# ddr32ss_EMIF_CTLCFG_0F308000h register map
Vendor: Texas Instruments
Registers are 32-bit, read-write, reset 0x0 unless marked. A register's access mark holds for its fields unless they carry their own. Offsets are as the file gives them; [hi:lo] are bit positions; {n}, {i} and the like mark numbered series.

## emif_ctlcfg (part 3 of 13)
{0x0+4i} emif_ctlcfg_DENALI_CTL_{i} (i=127..130)
  [31:0] TDFI_PHYMSTR_MAX_TYPE{i-127}_F1 — Defines the DFI 4.0v2 tPHYMSTR_MAX_TYPE{i-127} timing parameter [in DFI clocks], the maximum cycles that dfi_phymstr_req can be asserted following the assertion of dfi_phymstr_ack for dfi_phymstr_type={i-127}. If programmed to a non-zero, a timing violation will cause an interrupt and bit [0] set in the PHYMSTR_ERROR_STATUS parameter. FC=1 Reset Source: ctl_amod_g_rst_n
0x20C emif_ctlcfg_DENALI_CTL_131
  [15:0] PHYMSTR_DFI4_PROMOTE_THRESHOLD_F1 — Defines the DFI[4.0 and 4.0v2] PHY master request promotion number of regular [not long] counts until the high priority request is asserted. FC=1 Reset Source: ctl_amod_g_rst_n
0x210 emif_ctlcfg_DENALI_CTL_132
  [19:0] TDFI_PHYMSTR_RESP_F1 — Defines the DFI tPHYMSTR_RESP timing parameter [in DFI clocks], the maximum cycles between a dfi_phymstr_req assertion and a dfi_phymstr_ack assertion. If programmed to a non-zero, a timing violation will cause an interrupt and bit [1] to be set to 1 in the PHYMSTR_ERROR_STATUS parameter. FC=1 Reset Source: ctl_amod_g_rst_n
0x214 emif_ctlcfg_DENALI_CTL_133
  [31:0] TDFI_PHYMSTR_MAX_F2 — Defines the DFI tPHYMSTR_MAX timing parameter [in DFI clocks], the maximum cycles that dfi_phymstr_req can be asserted following the assertion of dfi_phymstr_ack. If programmed to a non-zero, a timing violation will cause an interrupt and bit [0] set in the PHYMSTR_ERROR_STATUS parameter. FC=2 Reset Source: ctl_amod_g_rst_n
{0x0+4i} emif_ctlcfg_DENALI_CTL_{i} (i=134..137)
  [31:0] TDFI_PHYMSTR_MAX_TYPE{i-134}_F2 — Defines the DFI 4.0v2 tPHYMSTR_MAX_TYPE{i-134} timing parameter [in DFI clocks], the maximum cycles that dfi_phymstr_req can be asserted following the assertion of dfi_phymstr_ack for dfi_phymstr_type={i-134}. If programmed to a non-zero, a timing violation will cause an interrupt and bit [0] set in the PHYMSTR_ERROR_STATUS parameter. FC=2 Reset Source: ctl_amod_g_rst_n
0x228 emif_ctlcfg_DENALI_CTL_138
  [15:0] PHYMSTR_DFI4_PROMOTE_THRESHOLD_F2 — Defines the DFI[4.0 and 4.0v2] PHY master request promotion number of regular [not long] counts until the high priority request is asserted. FC=2 Reset Source: ctl_amod_g_rst_n
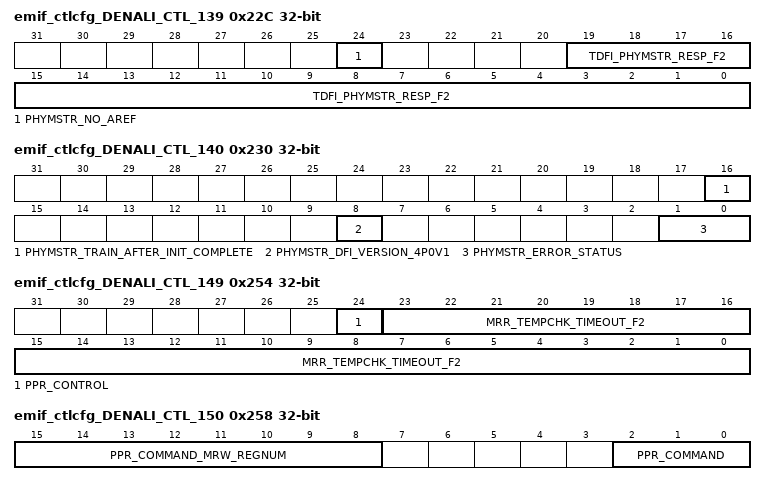
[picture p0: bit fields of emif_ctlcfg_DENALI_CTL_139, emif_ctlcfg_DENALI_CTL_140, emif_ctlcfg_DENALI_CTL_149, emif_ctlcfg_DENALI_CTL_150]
0x22C emif_ctlcfg_DENALI_CTL_139
  [24] PHYMSTR_NO_AREF — isables refreshes during the PHY master interface sequence. Set to 1 to disable. Refreshes during reset are only supported for DFI 4.0 and this parameter may be set or cleared for DFI 4.0. For all other DFI versions, this parameter must be set to 1. Reset Source: ctl_amod_g_rst_n
  [19:0] TDFI_PHYMSTR_RESP_F2 — Defines the DFI tPHYMSTR_RESP timing parameter [in DFI clocks], the maximum cycles between a dfi_phymstr_req assertion and a dfi_phymstr_ack assertion. If programmed to a non-zero, a timing violation will cause an interrupt and bit [1] to be set to 1 in the PHYMSTR_ERROR_STATUS parameter. FC=2 Reset Source: ctl_amod_g_rst_n
0x230 emif_ctlcfg_DENALI_CTL_140 access per field
  [16] PHYMSTR_TRAIN_AFTER_INIT_COMPLETE rw — Defines how the PHY will use the PHY Master Interface for training. Clear to 0 to perform training without the PHY Master Interface, or set to 1 to use the PHY Master Interface to gain control over the DFI bus after the dfi_init_complete signal assertion for the initial training. Default is cleared to 0. Reset Source: ctl_amod_g_rst_n
  [8] PHYMSTR_DFI_VERSION_4P0V1 rw — Defines the version of the DFI 4.0 specification supported. Clear to 0 for DFI 4.0 version 2 PHY Master Interface, or set to 1 for DFI 4.0 version 1 PHY Master Interface. Default is cleared to 0 for version 2. Reset Source: ctl_amod_g_rst_n
  [1:0] PHYMSTR_ERROR_STATUS ro — Identifies the source of any DFI PHY Master Interface errors. Value of 1 indicates a timing violation of the associated timing parameter. Bit [0] set indicates a TDFI_PHYMSTR_MAX or TDFI_PHYMSTR_TYPEn_MAX parmaeter violation and bit [1] set indicates a TDFI_PHYMSTR_RESP parameter violation. READ-ONLY Reset Source: ctl_amod_g_rst_n
0x234 emif_ctlcfg_DENALI_CTL_141
  [23:0] MRR_TEMPCHK_NORM_THRESHOLD_F0 — MRR temp check number of long counts until the normal priority request is asserted. FC=0 Reset Source: ctl_amod_g_rst_n
0x238 emif_ctlcfg_DENALI_CTL_142
  [23:0] MRR_TEMPCHK_HIGH_THRESHOLD_F0 — MRR temp check number of long counts until the high priority request is asserted. FC=0 Reset Source: ctl_amod_g_rst_n
0x23C emif_ctlcfg_DENALI_CTL_143
  [23:0] MRR_TEMPCHK_TIMEOUT_F0 — MRR temp check number of long counts until the timeout is asserted. FC=0 Reset Source: ctl_amod_g_rst_n
0x240 emif_ctlcfg_DENALI_CTL_144
  [23:0] MRR_TEMPCHK_NORM_THRESHOLD_F1 — MRR temp check number of long counts until the normal priority request is asserted. FC=1 Reset Source: ctl_amod_g_rst_n
0x244 emif_ctlcfg_DENALI_CTL_145
  [23:0] MRR_TEMPCHK_HIGH_THRESHOLD_F1 — MRR temp check number of long counts until the high priority request is asserted. FC=1 Reset Source: ctl_amod_g_rst_n
0x248 emif_ctlcfg_DENALI_CTL_146
  [23:0] MRR_TEMPCHK_TIMEOUT_F1 — MRR temp check number of long counts until the timeout is asserted. FC=1 Reset Source: ctl_amod_g_rst_n
0x24C emif_ctlcfg_DENALI_CTL_147
  [23:0] MRR_TEMPCHK_NORM_THRESHOLD_F2 — MRR temp check number of long counts until the normal priority request is asserted. FC=2 Reset Source: ctl_amod_g_rst_n
0x250 emif_ctlcfg_DENALI_CTL_148
  [23:0] MRR_TEMPCHK_HIGH_THRESHOLD_F2 — MRR temp check number of long counts until the high priority request is asserted. FC=2 Reset Source: ctl_amod_g_rst_n
0x254 emif_ctlcfg_DENALI_CTL_149
  [24] PPR_CONTROL — Enables the post-package repair feature. Set to 1 to enable. This parameter may only be programmed before initialization begins. Reset Source: ctl_amod_g_rst_n
  [23:0] MRR_TEMPCHK_TIMEOUT_F2 — MRR temp check number of long counts until the timeout is asserted. FC=2 Reset Source: ctl_amod_g_rst_n
0x258 emif_ctlcfg_DENALI_CTL_150 access per field
  [15:8] PPR_COMMAND_MRW_REGNUM rw — Specifies the mode register to be used. Clear to 0 for MRW0 or program to 4 for MRW4. All other values are reserved.. Reset Source: ctl_amod_g_rst_n
  [2:0] PPR_COMMAND wo — Specifies the type of PPR command. Program to 1 for pre-charge all, program to 2 for MRW, program to 3 for activate, or program to 5 for write. All other values are reserved. WRITE-ONLY Reset Source: ctl_amod_g_rst_n
0x25C emif_ctlcfg_DENALI_CTL_151
  [16:0] PPR_COMMAND_MRW_DATA — Specifies the data for the mode register write. Reset Source: ctl_amod_g_rst_n
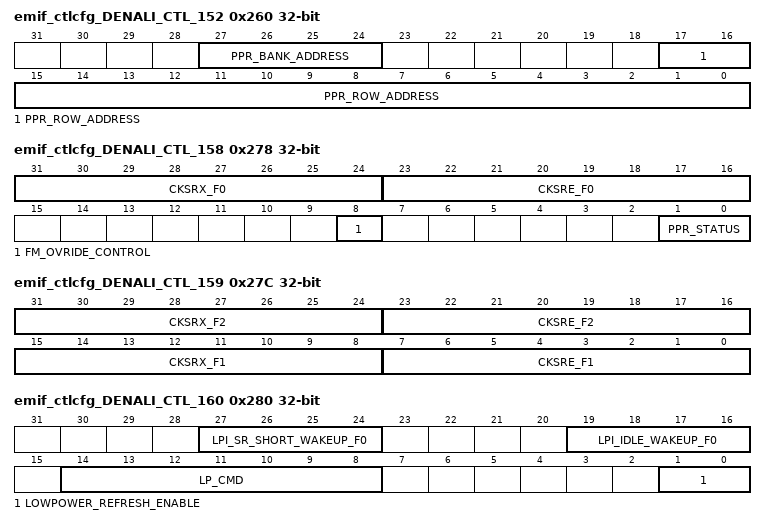
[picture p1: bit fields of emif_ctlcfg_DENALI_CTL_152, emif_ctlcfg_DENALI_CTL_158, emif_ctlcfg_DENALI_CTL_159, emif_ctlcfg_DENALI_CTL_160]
0x260 emif_ctlcfg_DENALI_CTL_152
  [27:24] PPR_BANK_ADDRESS — Specifies the bank for the row to be repaired. Reset Source: ctl_amod_g_rst_n
  [17:0] PPR_ROW_ADDRESS — Specifies the encoded row address to be repaired. Reset Source: ctl_amod_g_rst_n
0x264 emif_ctlcfg_DENALI_CTL_153
  [0] PPR_CS_ADDRESS — Specifies the chip select for the row to be repaired. Reset Source: ctl_amod_g_rst_n
{0x0+4i} emif_ctlcfg_DENALI_CTL_{i} (i=154..157)
  [31:0] PPR_DATA_{i-154} — Holds the data pattern to be written to memory for all data phases. This is specific to DDR4 memories. Reset Source: ctl_amod_g_rst_n
0x278 emif_ctlcfg_DENALI_CTL_158 access per field
  [31:24] CKSRX_F0 rw — Clock stable delay on self-refresh exit. FC=0 Reset Source: ctl_amod_g_rst_n
  [23:16] CKSRE_F0 rw — Clock hold delay on self-refresh entry. FC=0 Reset Source: ctl_amod_g_rst_n
  [8] FM_OVRIDE_CONTROL rw — Enables the FM Override feature. Set to 1 to enable. Reset Source: ctl_amod_g_rst_n
  [1:0] PPR_STATUS ro — Reports the status of the PPR operation. Bit [0] set indicates that PPR operations are now allowed and bit [1] set indicates if the last PPR command is complete. READ-ONLY Reset Source: ctl_amod_g_rst_n
0x27C emif_ctlcfg_DENALI_CTL_159
  [31:24] CKSRX_F2 — Clock stable delay on self-refresh exit. FC=2 Reset Source: ctl_amod_g_rst_n
  [23:16] CKSRE_F2 — Clock hold delay on self-refresh entry. FC=2 Reset Source: ctl_amod_g_rst_n
  [15:8] CKSRX_F1 — Clock stable delay on self-refresh exit. FC=1 Reset Source: ctl_amod_g_rst_n
  [7:0] CKSRE_F1 — Clock hold delay on self-refresh entry. FC=1 Reset Source: ctl_amod_g_rst_n
0x280 emif_ctlcfg_DENALI_CTL_160 access per field
  [27:24] LPI_SR_SHORT_WAKEUP_F0 rw — Defines the DFI tLP_WAKEUP timing parameter [in DFI clocks] to be driven when LPDDR4 memory is in the self-refresh short state [with or without memory clock gating]. For LPDDR4, SR_SHORT is used to send few commands so this wakeup time must be cleared to ZERO and no LPI request needs to be asserted. FC=0 Reset Source: ctl_amod_g_rst_n
  [19:16] LPI_IDLE_WAKEUP_F0 rw — Defines the DFI tLP_CTRL_WAKEUP timing parameter [in DFI clocks] to be driven when controller is idle. FC=0 Reset Source: ctl_amod_g_rst_n
  [14:8] LP_CMD wo — Low power software command request interface. Bit [0] controls exit, bit [1] controls entry, bits [4:2] define the low power state, bit [5] controls memory clock gating, bit [6] controls controller clock gating, and bit [7] controls lock. WRITE-ONLY Reset Source: ctl_amod_g_rst_n
  [1:0] LOWPOWER_REFRESH_ENABLE rw — Enable refreshes while in low power mode. Bit [0] controls cs0, bit [1] controls cs1, etc. Set each bit to 1 to disable. Reset Source: ctl_amod_g_rst_n
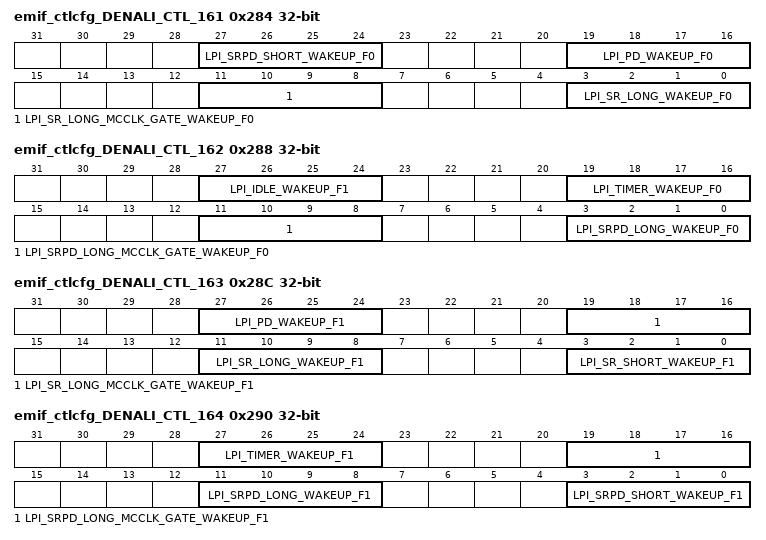
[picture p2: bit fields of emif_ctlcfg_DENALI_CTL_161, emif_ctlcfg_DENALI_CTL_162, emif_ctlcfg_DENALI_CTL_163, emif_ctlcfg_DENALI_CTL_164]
0x284 emif_ctlcfg_DENALI_CTL_161
  [27:24] LPI_SRPD_SHORT_WAKEUP_F0 — Defines the DFI tLP_WAKEUP timing parameter [in DFI clocks] to be driven when memory is in the self-refresh power-down short state [with or without memory clock gating]. FC=0 Reset Source: ctl_amod_g_rst_n
  [19:16] LPI_PD_WAKEUP_F0 — Defines the DFI tLP_WAKEUP timing parameter [in DFI clocks] to be driven when memory is in any of the power-down states [with or without memory clock gating]. FC=0 Reset Source: ctl_amod_g_rst_n
  [11:8] LPI_SR_LONG_MCCLK_GATE_WAKEUP_F0 — Defines the DFI tLP_WAKEUP timing parameter [in DFI clocks] to be driven when memory is in the self-refresh long with memory and controller clock gating state. FC=0 Reset Source: ctl_amod_g_rst_n
  [3:0] LPI_SR_LONG_WAKEUP_F0 — Defines the DFI tLP_WAKEUP timing parameter [in DFI clocks] to be driven when memory is in the self-refresh long state [with or without memory clock gating]. FC=0 Reset Source: ctl_amod_g_rst_n
0x288 emif_ctlcfg_DENALI_CTL_162
  [27:24] LPI_IDLE_WAKEUP_F1 — Defines the DFI tLP_CTRL_WAKEUP timing parameter [in DFI clocks] to be driven when controller is idle. FC=1 Reset Source: ctl_amod_g_rst_n
  [19:16] LPI_TIMER_WAKEUP_F0 — Defines the DFI tLP_WAKEUP timing parameter [in DFI clocks] to be driven when the LPI timer expires. FC=0 Reset Source: ctl_amod_g_rst_n
  [11:8] LPI_SRPD_LONG_MCCLK_GATE_WAKEUP_F0 — Defines the DFI tLP_WAKEUP timing parameter [in DFI clocks] to be driven when memory is in the self-refresh power-down long with memory and controller clock gating state. FC=0 Reset Source: ctl_amod_g_rst_n
  [3:0] LPI_SRPD_LONG_WAKEUP_F0 — Defines the DFI tLP_WAKEUP timing parameter [in DFI clocks] to be driven when memory is in the self-refresh power-down long state [with or without memory clock gating]. FC=0 Reset Source: ctl_amod_g_rst_n
0x28C emif_ctlcfg_DENALI_CTL_163
  [27:24] LPI_PD_WAKEUP_F1 — Defines the DFI tLP_WAKEUP timing parameter [in DFI clocks] to be driven when memory is in any of the power-down states [with or without memory clock gating]. FC=1 Reset Source: ctl_amod_g_rst_n
  [19:16] LPI_SR_LONG_MCCLK_GATE_WAKEUP_F1 — Defines the DFI tLP_WAKEUP timing parameter [in DFI clocks] to be driven when memory is in the self-refresh long with memory and controller clock gating state. FC=1 Reset Source: ctl_amod_g_rst_n
  [11:8] LPI_SR_LONG_WAKEUP_F1 — Defines the DFI tLP_WAKEUP timing parameter [in DFI clocks] to be driven when memory is in the self-refresh long state [with or without memory clock gating]. FC=1 Reset Source: ctl_amod_g_rst_n
  [3:0] LPI_SR_SHORT_WAKEUP_F1 — Defines the DFI tLP_WAKEUP timing parameter [in DFI clocks] to be driven when LPDDR4 memory is in the self-refresh short state [with or without memory clock gating]. For LPDDR4, SR_SHORT is used to send few commands so this wakeup time must be cleared to ZERO and no LPI request needs to be asserted. FC=1 Reset Source: ctl_amod_g_rst_n
0x290 emif_ctlcfg_DENALI_CTL_164
  [27:24] LPI_TIMER_WAKEUP_F1 — Defines the DFI tLP_WAKEUP timing parameter [in DFI clocks] to be driven when the LPI timer expires. FC=1 Reset Source: ctl_amod_g_rst_n
  [19:16] LPI_SRPD_LONG_MCCLK_GATE_WAKEUP_F1 — Defines the DFI tLP_WAKEUP timing parameter [in DFI clocks] to be driven when memory is in the self-refresh power-down long with memory and controller clock gating state. FC=1 Reset Source: ctl_amod_g_rst_n
  [11:8] LPI_SRPD_LONG_WAKEUP_F1 — Defines the DFI tLP_WAKEUP timing parameter [in DFI clocks] to be driven when memory is in the self-refresh power-down long state [with or without memory clock gating]. FC=1 Reset Source: ctl_amod_g_rst_n
  [3:0] LPI_SRPD_SHORT_WAKEUP_F1 — Defines the DFI tLP_WAKEUP timing parameter [in DFI clocks] to be driven when memory is in the self-refresh power-down short state [with or without memory clock gating]. FC=1 Reset Source: ctl_amod_g_rst_n
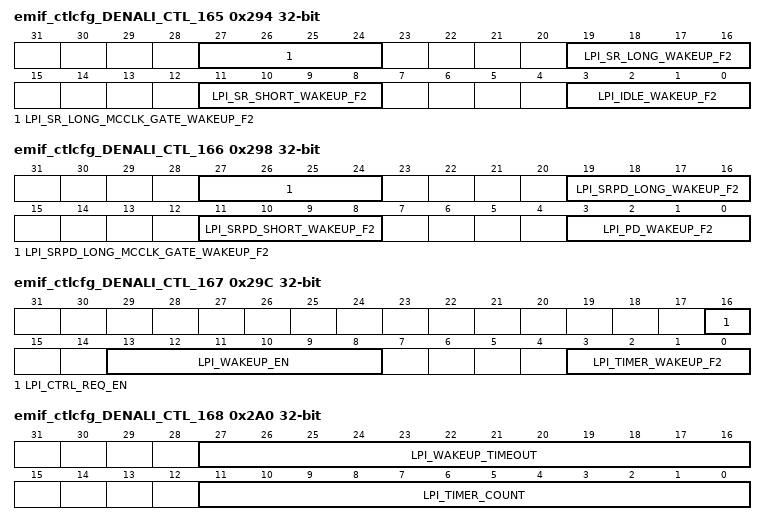
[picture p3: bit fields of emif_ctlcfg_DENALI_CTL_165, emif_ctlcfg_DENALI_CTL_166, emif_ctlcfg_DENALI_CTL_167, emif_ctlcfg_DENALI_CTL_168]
0x294 emif_ctlcfg_DENALI_CTL_165
  [27:24] LPI_SR_LONG_MCCLK_GATE_WAKEUP_F2 — Defines the DFI tLP_WAKEUP timing parameter [in DFI clocks] to be driven when memory is in the self-refresh long with memory and controller clock gating state. FC=2 Reset Source: ctl_amod_g_rst_n
  [19:16] LPI_SR_LONG_WAKEUP_F2 — Defines the DFI tLP_WAKEUP timing parameter [in DFI clocks] to be driven when memory is in the self-refresh long state [with or without memory clock gating]. FC=2 Reset Source: ctl_amod_g_rst_n
  [11:8] LPI_SR_SHORT_WAKEUP_F2 — Defines the DFI tLP_WAKEUP timing parameter [in DFI clocks] to be driven when LPDDR4 memory is in the self-refresh short state [with or without memory clock gating]. For LPDDR4, SR_SHORT is used to send few commands so this wakeup time must be cleared to ZERO and no LPI request needs to be asserted. FC=2 Reset Source: ctl_amod_g_rst_n
  [3:0] LPI_IDLE_WAKEUP_F2 — Defines the DFI tLP_CTRL_WAKEUP timing parameter [in DFI clocks] to be driven when controller is idle. FC=2 Reset Source: ctl_amod_g_rst_n
0x298 emif_ctlcfg_DENALI_CTL_166
  [27:24] LPI_SRPD_LONG_MCCLK_GATE_WAKEUP_F2 — Defines the DFI tLP_WAKEUP timing parameter [in DFI clocks] to be driven when memory is in the self-refresh power-down long with memory and controller clock gating state. FC=2 Reset Source: ctl_amod_g_rst_n
  [19:16] LPI_SRPD_LONG_WAKEUP_F2 — Defines the DFI tLP_WAKEUP timing parameter [in DFI clocks] to be driven when memory is in the self-refresh power-down long state [with or without memory clock gating]. FC=2 Reset Source: ctl_amod_g_rst_n
  [11:8] LPI_SRPD_SHORT_WAKEUP_F2 — Defines the DFI tLP_WAKEUP timing parameter [in DFI clocks] to be driven when memory is in the self-refresh power-down short state [with or without memory clock gating]. FC=2 Reset Source: ctl_amod_g_rst_n
  [3:0] LPI_PD_WAKEUP_F2 — Defines the DFI tLP_WAKEUP timing parameter [in DFI clocks] to be driven when memory is in any of the power-down states [with or without memory clock gating]. FC=2 Reset Source: ctl_amod_g_rst_n
0x29C emif_ctlcfg_DENALI_CTL_167
  [16] LPI_CTRL_REQ_EN — Enables the dfi_lpi_ctrl_req signal for the LPI. This signal is only relevant for DFI versions 3.1 and beyond. Set to 1 to enable or clear to 0 to disable. Reset Source: ctl_amod_g_rst_n
  [13:8] LPI_WAKEUP_EN — Enables the various low power state wakeup parameters for LPI request uses. Bit [0] enables controller idle wakeup, bit [1] enables power-down wakeup, bit [2] enables either self-refresh short, self-refresh long with or without mem clk gating, either self-refresh power-down short, or self-refresh power-down long with or without mem clk gating, bit [3] enables self-refresh long with mem and ctlr clk gating or self-refresh power-down long with mem and ctlr clk gating, bit [4] enables the LPI timer expire wakeup, and bit [5] is reserved. Set each bit to 1 to enable the respective LP_WAKEUP value for the LPI request. Reset Source: ctl_amod_g_rst_n
  [3:0] LPI_TIMER_WAKEUP_F2 — Defines the DFI tLP_WAKEUP timing parameter [in DFI clocks] to be driven when the LPI timer expires. FC=2 Reset Source: ctl_amod_g_rst_n
0x2A0 emif_ctlcfg_DENALI_CTL_168
  [27:16] LPI_WAKEUP_TIMEOUT — Defines the LPI timeout time, the maximum cycles between a dfi_lp_req de-assertion and a dfi_lp_ack de-assertion. If this value is exceeded, an interrupt will occur. Reset Source: ctl_amod_g_rst_n
  [11:0] LPI_TIMER_COUNT — Defines the LPI timer count. Reset Source: ctl_amod_g_rst_n
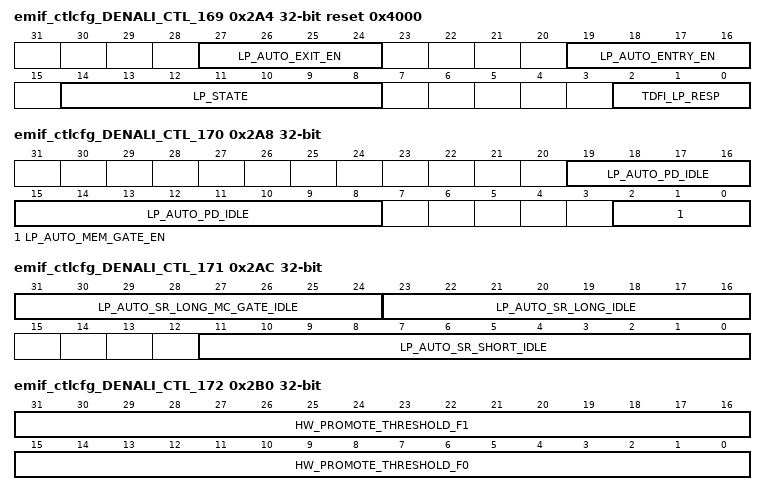
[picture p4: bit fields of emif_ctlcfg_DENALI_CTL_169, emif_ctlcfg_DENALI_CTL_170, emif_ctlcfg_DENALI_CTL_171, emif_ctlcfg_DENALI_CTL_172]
0x2A4 emif_ctlcfg_DENALI_CTL_169 access per field reset 0x4000
  [27:24] LP_AUTO_EXIT_EN rw — Enable auto exit from each of the low power states when a read or write command enters the command queue. Bit [0] controls power-down, bit [1] controls self-refresh long or self-refresh power-down long, bit [2] controls self-refresh long with memory and controller clock gating or self-refresh power-down long with memory and controller clock gating, and bit [3] controls self-refresh short or self-refresh power-down short. Set each bit to 1 to enable. Reset Source: ctl_amod_g_rst_n
  [19:16] LP_AUTO_ENTRY_EN rw — Enable auto entry into each of the low power states when the associated idle timer expires. Bit [0] controls power-down, bit [1] controls self-refresh long or self-refresh power-down long, bit [2] controls self-refresh long with memory and controller clock gating or self-refresh power-down long with memory and controller clock gating, and bit [3] controls self-refresh short or self-refresh power-down short. Set each bit to 1 to enable. Reset Source: ctl_amod_g_rst_n
  [14:8] LP_STATE ro — Low power state status parameter. Bits [5:0] indicate the current low power state and bit [6] set indicates that status bits are valid. READ-ONLY Reset Source: ctl_amod_g_rst_n
  [2:0] TDFI_LP_RESP rw — Defines the DFI tLP_RESP timing parameter [in DFI clocks], the maximum cycles between a dfi_lp_req assertion and a dfi_lp_ack assertion. Reset Source: ctl_amod_g_rst_n
0x2A8 emif_ctlcfg_DENALI_CTL_170
  [19:8] LP_AUTO_PD_IDLE — Defines the idle time [in controller clocks] until the controller will automatically issue an entry into one of the power-down low power states. Reset Source: ctl_amod_g_rst_n
  [2:0] LP_AUTO_MEM_GATE_EN — Enable memory clock gating when entering a low power state via the auto low power counters. Bit [0] controls power-down, bit [1] controls self-refresh long or self-refresh power-down long, and bit [2] controls self-refresh short or self-refresh power-down short. Set each bit to 1 to enable. Reset Source: ctl_amod_g_rst_n
0x2AC emif_ctlcfg_DENALI_CTL_171
  [31:24] LP_AUTO_SR_LONG_MC_GATE_IDLE — Defines the idle time [in long counts] until the controller will automatically issue an entry into the self-refresh long with memory and controller clock gating or self-refresh power-down long with memory and controller clock gating low power states. Reset Source: ctl_amod_g_rst_n
  [23:16] LP_AUTO_SR_LONG_IDLE — Defines the idle time [in long counts] until the controller will automatically issue an entry into the self-refresh long or self-refresh power-down long [with or without memory clock gating] low power states. Reset Source: ctl_amod_g_rst_n
  [11:0] LP_AUTO_SR_SHORT_IDLE — Defines the idle time [in controller clocks] until the controller will automatically issue an entry into the self-refresh short or self-refresh power-down short [with or without memory clock gating] low power states. Reset Source: ctl_amod_g_rst_n
0x2B0 emif_ctlcfg_DENALI_CTL_172
  [31:16] HW_PROMOTE_THRESHOLD_F1 — HW interface promotion number of long counts until the high priority request is asserted. FC=1 Reset Source: ctl_amod_g_rst_n
  [15:0] HW_PROMOTE_THRESHOLD_F0 — HW interface promotion number of long counts until the high priority request is asserted. FC=0 Reset Source: ctl_amod_g_rst_n
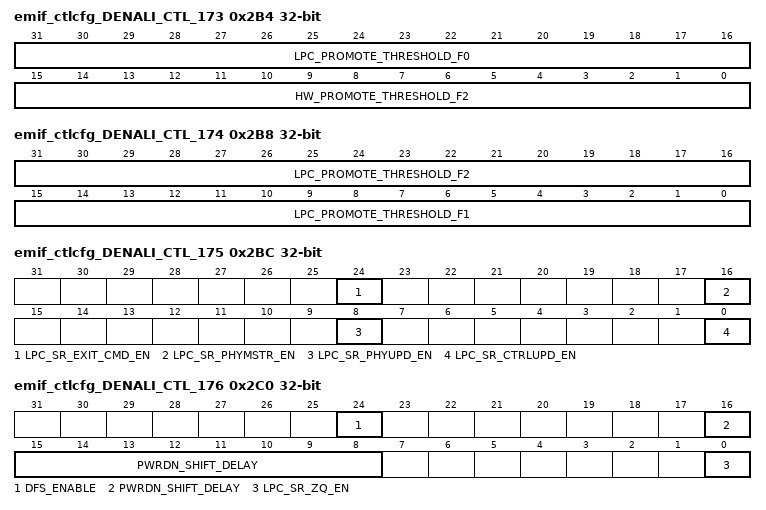
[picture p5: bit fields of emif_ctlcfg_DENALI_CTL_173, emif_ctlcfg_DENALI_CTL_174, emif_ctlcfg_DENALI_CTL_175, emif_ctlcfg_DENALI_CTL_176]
0x2B4 emif_ctlcfg_DENALI_CTL_173
  [31:16] LPC_PROMOTE_THRESHOLD_F0 — LPC promotion number of long counts until the high priority request is asserted for frequency copy 4. Applies to SW and auto low power commands. FC=0 Reset Source: ctl_amod_g_rst_n
  [15:0] HW_PROMOTE_THRESHOLD_F2 — HW interface promotion number of long counts until the high priority request is asserted. FC=2 Reset Source: ctl_amod_g_rst_n
0x2B8 emif_ctlcfg_DENALI_CTL_174
  [31:16] LPC_PROMOTE_THRESHOLD_F2 — LPC promotion number of long counts until the high priority request is asserted for frequency copy 4. Applies to SW and auto low power commands. FC=2 Reset Source: ctl_amod_g_rst_n
  [15:0] LPC_PROMOTE_THRESHOLD_F1 — LPC promotion number of long counts until the high priority request is asserted for frequency copy 4. Applies to SW and auto low power commands. FC=1 Reset Source: ctl_amod_g_rst_n
0x2BC emif_ctlcfg_DENALI_CTL_175
  [24] LPC_SR_EXIT_CMD_EN — Enable LPC to execute any of the commands on self-refresh exit while exiting. Set to 1 to enable. Reset Source: ctl_amod_g_rst_n
  [16] LPC_SR_PHYMSTR_EN — Enable LPC to execute a DFI PHY Master request on a self-refresh exit sequence. Set to 1 to enable. Reset Source: ctl_amod_g_rst_n
  [8] LPC_SR_PHYUPD_EN — Enable LPC to execute a DFI PHY update on a self-refresh exit sequence. Set to 1 to enable. Reset Source: ctl_amod_g_rst_n
  [0] LPC_SR_CTRLUPD_EN — Enable LPC to execute a DFI control update on a self-refresh exit sequence. Set to 1 to enable. Reset Source: ctl_amod_g_rst_n
0x2C0 emif_ctlcfg_DENALI_CTL_176
  [24] DFS_ENABLE — Enable hardware dynamic frequency scaling. Set to 1 to enable. Reset Source: ctl_amod_g_rst_n
  [16:8] PWRDN_SHIFT_DELAY — This parameter should be programmed to zero. Manual adjustment of inhibit_pwrdn_shift in memcd_strategy_data_delay. Reset Source: ctl_amod_g_rst_n
  [0] LPC_SR_ZQ_EN — Enable LPC to execute a ZQ calibration on a self-refresh exit sequence. Set to 1 to enable. Reset Source: ctl_amod_g_rst_n
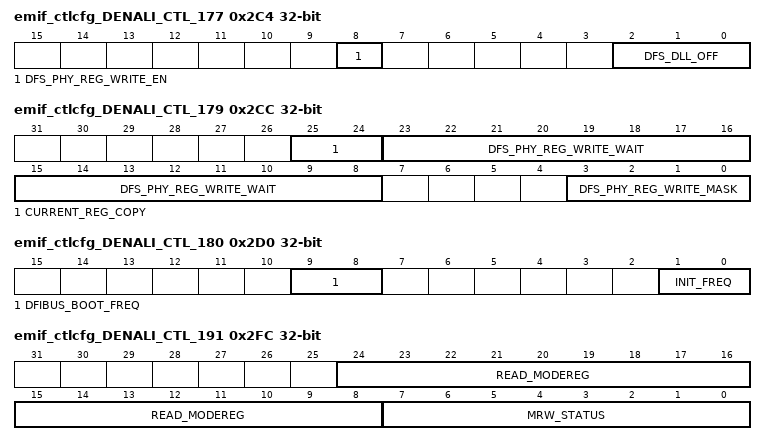
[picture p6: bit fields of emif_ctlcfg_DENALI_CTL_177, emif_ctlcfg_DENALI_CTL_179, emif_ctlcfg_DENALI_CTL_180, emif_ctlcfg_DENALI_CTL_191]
0x2C4 emif_ctlcfg_DENALI_CTL_177
  [8] DFS_PHY_REG_WRITE_EN — Enable a register write to the PHY during a frequency change. Set to 1 to enable. Reset Source: ctl_amod_g_rst_n
  [2:0] DFS_DLL_OFF — Defines if the memory DLL must be off for the associated frequency set. Bit [0] corresponds to frequency set 0, bit [1] corresponds to frequency set 1, etc. Set each bit to 1 to require DLL off. Reset Source: ctl_amod_g_rst_n
0x2C8 emif_ctlcfg_DENALI_CTL_178
  [31:0] DFS_PHY_REG_WRITE_ADDR — Register address which will be written during a frequency change. Must be a PHY register address. Reset Source: ctl_amod_g_rst_n
0x2CC emif_ctlcfg_DENALI_CTL_179 access per field
  [25:24] CURRENT_REG_COPY ro — Indicates the current copy of timing parameters that is in use by the controller. Reset Source: ctl_amod_g_rst_n
  [23:8] DFS_PHY_REG_WRITE_WAIT rw — Defines the number of DFI PHY clocks that the controller will wait after issuing the register write to the PHY during a frequency change. Reset Source: ctl_amod_g_rst_n
  [3:0] DFS_PHY_REG_WRITE_MASK rw — Register mask which will be written during a frequency change. Reset Source: ctl_amod_g_rst_n
0x2D0 emif_ctlcfg_DENALI_CTL_180
  [9:8] DFIBUS_BOOT_FREQ — Defines the DFI bus boot frequency register copy Reset Source: ctl_amod_g_rst_n
  [1:0] INIT_FREQ — Specifies what frequency register copy will be in use by the memory after initialization completes. Reset Source: ctl_amod_g_rst_n
{0x0+4i} emif_ctlcfg_DENALI_CTL_{i} (i=181..183)
  [31:0] DFS_PHY_REG_WRITE_DATA_F{i-181} — Register data which will be written during a frequency change. FC={i-181} Reset Source: ctl_amod_g_rst_n
0x2E0 emif_ctlcfg_DENALI_CTL_184
  [23:0] TDFI_INIT_START_F0 — Defines the DFI tINIT_START timing parameter [in DFI clocks], the maximum number of cycles between a dfi_init_start assertion and a dfi_init_complete de-assertion from the PHY. FC=0 Reset Source: ctl_amod_g_rst_n
0x2E4 emif_ctlcfg_DENALI_CTL_185
  [23:0] TDFI_INIT_COMPLETE_F0 — Defines the DFI tINIT_COMPLETE timing parameter [in DFI clocks], the maximum cycles between a dfi_init_start de-assertion and a dfi_init_complete assertion from the PHY. FC=0 Reset Source: ctl_amod_g_rst_n
0x2E8 emif_ctlcfg_DENALI_CTL_186
  [23:0] TDFI_INIT_START_F1 — Defines the DFI tINIT_START timing parameter [in DFI clocks], the maximum number of cycles between a dfi_init_start assertion and a dfi_init_complete de-assertion from the PHY. FC=1 Reset Source: ctl_amod_g_rst_n
0x2EC emif_ctlcfg_DENALI_CTL_187
  [23:0] TDFI_INIT_COMPLETE_F1 — Defines the DFI tINIT_COMPLETE timing parameter [in DFI clocks], the maximum cycles between a dfi_init_start de-assertion and a dfi_init_complete assertion from the PHY. FC=1 Reset Source: ctl_amod_g_rst_n
0x2F0 emif_ctlcfg_DENALI_CTL_188
  [23:0] TDFI_INIT_START_F2 — Defines the DFI tINIT_START timing parameter [in DFI clocks], the maximum number of cycles between a dfi_init_start assertion and a dfi_init_complete de-assertion from the PHY. FC=2 Reset Source: ctl_amod_g_rst_n
0x2F4 emif_ctlcfg_DENALI_CTL_189
  [23:0] TDFI_INIT_COMPLETE_F2 — Defines the DFI tINIT_COMPLETE timing parameter [in DFI clocks], the maximum cycles between a dfi_init_start de-assertion and a dfi_init_complete assertion from the PHY. FC=2 Reset Source: ctl_amod_g_rst_n
0x2F8 emif_ctlcfg_DENALI_CTL_190
  [26:0] WRITE_MODEREG — Write memory mode register data to the DRAMs. Bits [7:0] define the memory mode register number if bit [23] is set, bits [15:8] define the chip select if bit [24] is clear, bits [23:16] define which memory mode register/s to write, bit [24] defines whether all chip selects will be written, and bit [25] triggers the write. Reset Source: ctl_amod_g_rst_n
0x2FC emif_ctlcfg_DENALI_CTL_191 access per field
  [24:8] READ_MODEREG rw — Read the specified memory mode register from specified chip when start bit set. Bits [7:0] define the memory mode register and bits [15:8] define the chip select. Set bit [16] to 1 to trigger. Reset Source: ctl_amod_g_rst_n
  [7:0] MRW_STATUS ro — Write memory mode register status. Bit [0] set indicates a WRITE_MODEREG parameter programming error. Bit [1] set indicates a PASR error. Bit [2] is Reserved. Bit [3] set indicates a self-refresh or deep power-down error. Bit [4] set indicates that a write to MR3 or MR11 was attempted [WRITE_MODEREG bit [25] was asserted with bit [17] set, or bit [23] was asserted with bits [7:0] defining MR3 or MR11] during tZQCAL after a ZQ calibration start command. READ-ONLY Reset Source: ctl_amod_g_rst_n
0x300 emif_ctlcfg_DENALI_CTL_192 ro
  [31:0] PERIPHERAL_MRR_DATA_0 — Data and chip returned from memory mode register read requested by the READ_MODEREG parameter. Bits [7:0] indicate the read data and bits [15:8] indicate the chip. READ-ONLY Reset Source: ctl_amod_g_rst_n
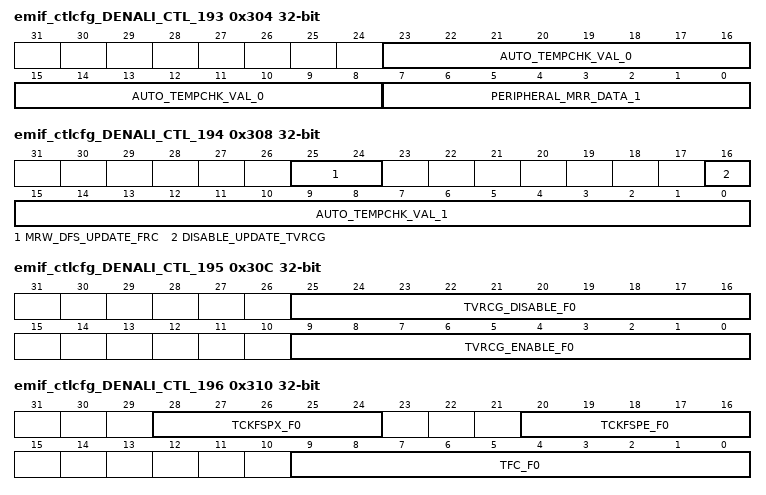
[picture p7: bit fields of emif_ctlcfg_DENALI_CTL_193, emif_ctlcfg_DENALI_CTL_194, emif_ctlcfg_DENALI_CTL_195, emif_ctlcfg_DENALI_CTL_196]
0x304 emif_ctlcfg_DENALI_CTL_193 ro
  [23:8] AUTO_TEMPCHK_VAL_0 — MR4 data for all devices accessed by automatic MRR commands. Bits [3:0] correlate to the device on the lower byte, bits [7:4] correlate to the devices on the 2nd byte etc. Value indicates the OP7, OP2, OP1 and OP0 bits. READ-ONLY. Reset Source: ctl_amod_g_rst_n
  [7:0] PERIPHERAL_MRR_DATA_1 — Data and chip returned from memory mode register read requested by the READ_MODEREG parameter. Bits [7:0] indicate the read data and bits [15:8] indicate the chip. READ-ONLY Reset Source: ctl_amod_g_rst_n
0x308 emif_ctlcfg_DENALI_CTL_194 access per field
  [25:24] MRW_DFS_UPDATE_FRC rw — Defines the frequency register set to use when doing a software MRW with WRITE_MODEREG bit [26]. Reset Source: ctl_amod_g_rst_n
  [16] DISABLE_UPDATE_TVRCG rw — Bypass changing for TVRCG during a DFS operation. Set to 1 to skip TVRCG. Reset Source: ctl_amod_g_rst_n
  [15:0] AUTO_TEMPCHK_VAL_1 ro — MR4 data for all devices accessed by automatic MRR commands. Bits [3:0] correlate to the device on the lower byte, bits [7:4] correlate to the devices on the 2nd byte etc. Value indicates the OP7, OP2, OP1 and OP0 bits. READ-ONLY. Reset Source: ctl_amod_g_rst_n
0x30C emif_ctlcfg_DENALI_CTL_195
  [25:16] TVRCG_DISABLE_F0 — JEDEC TVRCG_DISABLE time. FC=0 Reset Source: ctl_amod_g_rst_n
  [9:0] TVRCG_ENABLE_F0 — JEDEC TVRCG_ENABLE time. FC=0 Reset Source: ctl_amod_g_rst_n
0x310 emif_ctlcfg_DENALI_CTL_196
  [28:24] TCKFSPX_F0 — JEDEC TCKFSPX, the frequency set point switching time. FC=0 Reset Source: ctl_amod_g_rst_n
  [20:16] TCKFSPE_F0 — JEDEC TCKFSPE, the frequency set point switching time. FC=0 Reset Source: ctl_amod_g_rst_n
  [9:0] TFC_F0 — JEDEC TFC, the frequency set point switching time. FC=0 Reset Source: ctl_amod_g_rst_n
0x314 emif_ctlcfg_DENALI_CTL_197
  [19:0] TVREF_LONG_F0 — JEDEC TVREF, design will always use the long value. FC=0 Reset Source: ctl_amod_g_rst_n
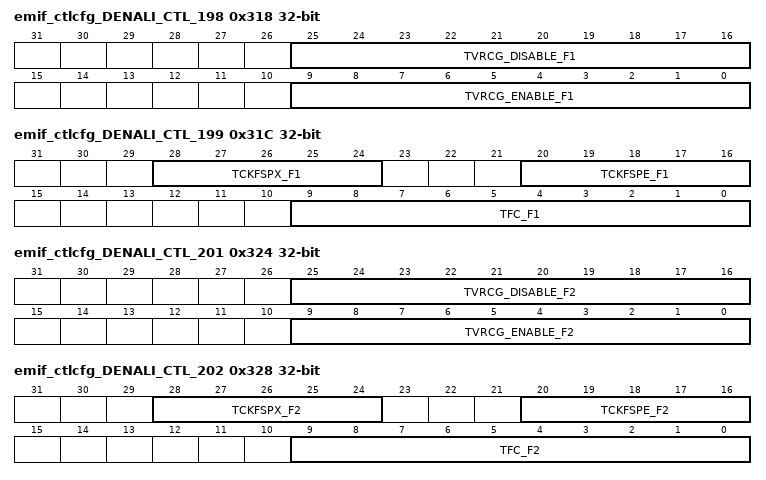
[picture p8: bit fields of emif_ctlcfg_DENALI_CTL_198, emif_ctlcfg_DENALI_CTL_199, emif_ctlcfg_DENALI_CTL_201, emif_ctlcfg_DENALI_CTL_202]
0x318 emif_ctlcfg_DENALI_CTL_198
  [25:16] TVRCG_DISABLE_F1 — JEDEC TVRCG_DISABLE time. FC=1 Reset Source: ctl_amod_g_rst_n
  [9:0] TVRCG_ENABLE_F1 — JEDEC TVRCG_ENABLE time. FC=1 Reset Source: ctl_amod_g_rst_n
0x31C emif_ctlcfg_DENALI_CTL_199
  [28:24] TCKFSPX_F1 — JEDEC TCKFSPX, the frequency set point switching time. FC=1 Reset Source: ctl_amod_g_rst_n
  [20:16] TCKFSPE_F1 — JEDEC TCKFSPE, the frequency set point switching time. FC=1 Reset Source: ctl_amod_g_rst_n
  [9:0] TFC_F1 — JEDEC TFC, the frequency set point switching time. FC=1 Reset Source: ctl_amod_g_rst_n
0x320 emif_ctlcfg_DENALI_CTL_200
  [19:0] TVREF_LONG_F1 — JEDEC TVREF, design will always use the long value. FC=1 Reset Source: ctl_amod_g_rst_n
0x324 emif_ctlcfg_DENALI_CTL_201
  [25:16] TVRCG_DISABLE_F2 — JEDEC TVRCG_DISABLE time. FC=2 Reset Source: ctl_amod_g_rst_n
  [9:0] TVRCG_ENABLE_F2 — JEDEC TVRCG_ENABLE time. FC=2 Reset Source: ctl_amod_g_rst_n
0x328 emif_ctlcfg_DENALI_CTL_202
  [28:24] TCKFSPX_F2 — JEDEC TCKFSPX, the frequency set point switching time. FC=2 Reset Source: ctl_amod_g_rst_n
  [20:16] TCKFSPE_F2 — JEDEC TCKFSPE, the frequency set point switching time. FC=2 Reset Source: ctl_amod_g_rst_n
  [9:0] TFC_F2 — JEDEC TFC, the frequency set point switching time. FC=2 Reset Source: ctl_amod_g_rst_n
0x32C emif_ctlcfg_DENALI_CTL_203
  [19:0] TVREF_LONG_F2 — JEDEC TVREF, design will always use the long value. FC=2 Reset Source: ctl_amod_g_rst_n
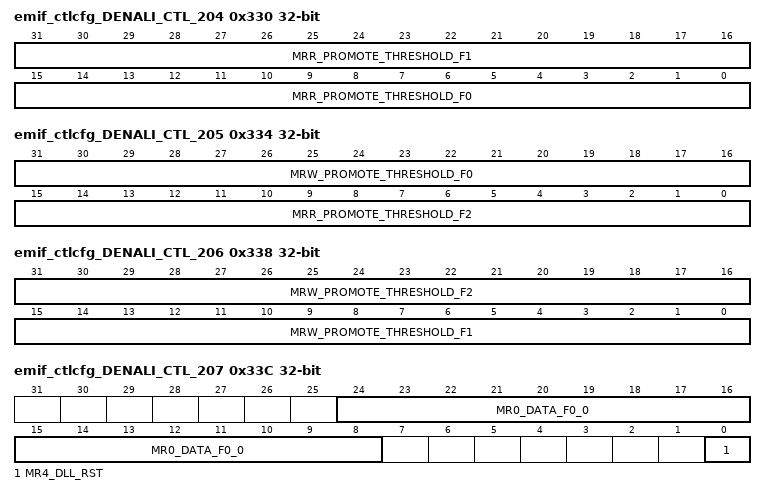
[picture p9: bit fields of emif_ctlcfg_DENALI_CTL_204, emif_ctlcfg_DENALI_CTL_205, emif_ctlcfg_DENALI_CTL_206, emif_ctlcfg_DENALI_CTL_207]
0x330 emif_ctlcfg_DENALI_CTL_204
  [31:16] MRR_PROMOTE_THRESHOLD_F1 — MRR promotion number of long counts until the high priority request is asserted. Applies to SW MRR commands. FC=1 Reset Source: ctl_amod_g_rst_n
  [15:0] MRR_PROMOTE_THRESHOLD_F0 — MRR promotion number of long counts until the high priority request is asserted. Applies to SW MRR commands. FC=0 Reset Source: ctl_amod_g_rst_n
0x334 emif_ctlcfg_DENALI_CTL_205
  [31:16] MRW_PROMOTE_THRESHOLD_F0 — MRW promotion number of long counts until the high priority request is asserted. Applies to SW MRW commands. FC=0 Reset Source: ctl_amod_g_rst_n
  [15:0] MRR_PROMOTE_THRESHOLD_F2 — MRR promotion number of long counts until the high priority request is asserted. Applies to SW MRR commands. FC=2 Reset Source: ctl_amod_g_rst_n
0x338 emif_ctlcfg_DENALI_CTL_206
  [31:16] MRW_PROMOTE_THRESHOLD_F2 — MRW promotion number of long counts until the high priority request is asserted. Applies to SW MRW commands. FC=2 Reset Source: ctl_amod_g_rst_n
  [15:0] MRW_PROMOTE_THRESHOLD_F1 — MRW promotion number of long counts until the high priority request is asserted. Applies to SW MRW commands. FC=1 Reset Source: ctl_amod_g_rst_n
0x33C emif_ctlcfg_DENALI_CTL_207
  [24:8] MR0_DATA_F0_0 — Data to program into memory mode register 0. FC=0 Reset Source: ctl_amod_g_rst_n
  [0] MR4_DLL_RST — Asserted if DRAM DLL Reset bit resides in MR4. Reset Source: ctl_amod_g_rst_n
0x340 emif_ctlcfg_DENALI_CTL_208
  [16:0] MR1_DATA_F0_0 — Data to program into memory mode register 1. FC=0 Reset Source: ctl_amod_g_rst_n
0x344 emif_ctlcfg_DENALI_CTL_209
  [16:0] MR2_DATA_F0_0 — Data to program into memory mode register 2. FC=0 Reset Source: ctl_amod_g_rst_n
{0x0+4i} emif_ctlcfg_DENALI_CTL_{i} (i=210..212)
  [16:0] MR{i-210}_DATA_F1_0 — Data to program into memory mode register {i-210}. FC=1 Reset Source: ctl_amod_g_rst_n
{0x0+4i} emif_ctlcfg_DENALI_CTL_{i} (i=213..215)
  [16:0] MR{i-213}_DATA_F2_0 — Data to program into memory mode register {i-213}. FC=2 Reset Source: ctl_amod_g_rst_n
{0x0+4i} emif_ctlcfg_DENALI_CTL_{i} (i=216..218)
  [16:0] MR{i-216}_DATA_F0_1 — Data to program into memory mode register {i-216}. FC=0 Reset Source: ctl_amod_g_rst_n
{0x0+4i} emif_ctlcfg_DENALI_CTL_{i} (i=219..221)
  [16:0] MR{i-219}_DATA_F1_1 — Data to program into memory mode register {i-219}. FC=1 Reset Source: ctl_amod_g_rst_n
{0x0+4i} emif_ctlcfg_DENALI_CTL_{i} (i=222..224)
  [16:0] MR{i-222}_DATA_F2_1 — Data to program into memory mode register {i-222}. FC=2 Reset Source: ctl_amod_g_rst_n
0x384 emif_ctlcfg_DENALI_CTL_225
  [16:0] MRSINGLE_DATA_0 — Data to program into memory mode register single write. Reset Source: ctl_amod_g_rst_n
0x388 emif_ctlcfg_DENALI_CTL_226
  [16:0] MRSINGLE_DATA_1 — Data to program into memory mode register single write. Reset Source: ctl_amod_g_rst_n
{0x0+4i} emif_ctlcfg_DENALI_CTL_{i} (i=227..229)
  [16:0] MR3_DATA_F{i-227}_0 — Data to program into memory mode register 3. FC={i-227} Reset Source: ctl_amod_g_rst_n
{0x0+4i} emif_ctlcfg_DENALI_CTL_{i} (i=230..232)
  [16:0] MR3_DATA_F{i-230}_1 — Data to program into memory mode register 3. FC={i-230} Reset Source: ctl_amod_g_rst_n
{0x0+4i} emif_ctlcfg_DENALI_CTL_{i} (i=233..235)
  [16:0] MR4_DATA_F{i-233}_0 — Data to program into memory mode register 4. FC={i-233} Reset Source: ctl_amod_g_rst_n
{0x0+4i} emif_ctlcfg_DENALI_CTL_{i} (i=236..238)
  [16:0] MR4_DATA_F{i-236}_1 — Data to program into memory mode register 4. FC={i-236} Reset Source: ctl_amod_g_rst_n
{0x0+4i} emif_ctlcfg_DENALI_CTL_{i} (i=239..241)
  [16:0] MR5_DATA_F{i-239}_0 — Data to program into memory mode register 5. FC={i-239} Reset Source: ctl_amod_g_rst_n
{0x0+4i} emif_ctlcfg_DENALI_CTL_{i} (i=242..244)
  [16:0] MR5_DATA_F{i-242}_1 — Data to program into memory mode register 5. FC={i-242} Reset Source: ctl_amod_g_rst_n
{0x0+4i} emif_ctlcfg_DENALI_CTL_{i} (i=245..247)
  [16:0] MR6_DATA_F{i-245}_0 — Data to program into memory mode register 6. FC={i-245} Reset Source: ctl_amod_g_rst_n
0x3E0 emif_ctlcfg_DENALI_CTL_248
  [16:0] MR6_DATA_F0_1 — Data to program into memory mode register 6. FC=0 Reset Source: ctl_amod_g_rst_n
0x3E4 emif_ctlcfg_DENALI_CTL_249
  [16:0] MR6_DATA_F1_1 — Data to program into memory mode register 6. FC=1 Reset Source: ctl_amod_g_rst_n
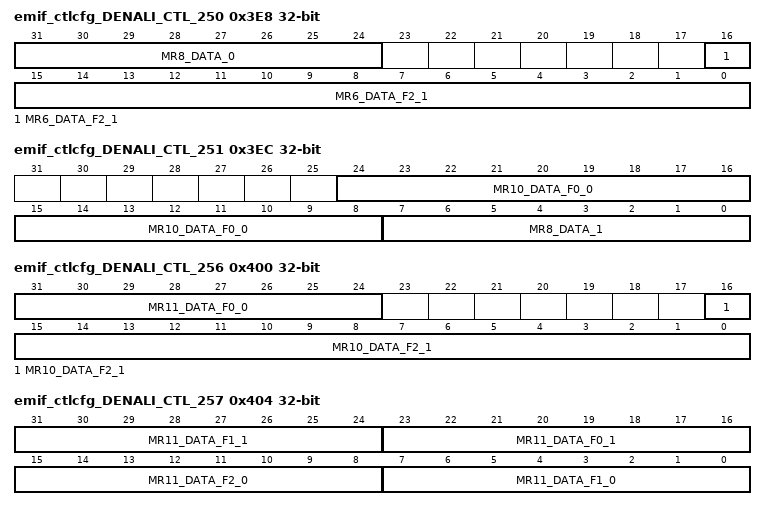
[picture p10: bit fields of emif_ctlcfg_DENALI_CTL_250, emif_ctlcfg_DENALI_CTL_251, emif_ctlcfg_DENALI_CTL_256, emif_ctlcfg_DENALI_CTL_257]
0x3E8 emif_ctlcfg_DENALI_CTL_250 access per field
  [31:24] MR8_DATA_0 ro — Data to program into memory mode register 8 for each chip select. READ-ONLY. Reset Source: ctl_amod_g_rst_n
  [16:0] MR6_DATA_F2_1 rw — Data to program into memory mode register 6. FC=2 Reset Source: ctl_amod_g_rst_n
0x3EC emif_ctlcfg_DENALI_CTL_251 access per field
  [24:8] MR10_DATA_F0_0 rw — Data to program into memory mode register 10. FC=0 Reset Source: ctl_amod_g_rst_n
  [7:0] MR8_DATA_1 ro — Data to program into memory mode register 8 for each chip select. READ-ONLY. Reset Source: ctl_amod_g_rst_n
0x3F0 emif_ctlcfg_DENALI_CTL_252
  [16:0] MR10_DATA_F1_0 — Data to program into memory mode register 10. FC=1 Reset Source: ctl_amod_g_rst_n
0x3F4 emif_ctlcfg_DENALI_CTL_253
  [16:0] MR10_DATA_F2_0 — Data to program into memory mode register 10. FC=2 Reset Source: ctl_amod_g_rst_n
0x3F8 emif_ctlcfg_DENALI_CTL_254
  [16:0] MR10_DATA_F0_1 — Data to program into memory mode register 10. FC=0 Reset Source: ctl_amod_g_rst_n
0x3FC emif_ctlcfg_DENALI_CTL_255
  [16:0] MR10_DATA_F1_1 — Data to program into memory mode register 10. FC=1 Reset Source: ctl_amod_g_rst_n
0x400 emif_ctlcfg_DENALI_CTL_256
  [31:24] MR11_DATA_F0_0 — Data to program into memory mode register 11. FC=0 Reset Source: ctl_amod_g_rst_n
  [16:0] MR10_DATA_F2_1 — Data to program into memory mode register 10. FC=2 Reset Source: ctl_amod_g_rst_n
0x404 emif_ctlcfg_DENALI_CTL_257
  [31:24] MR11_DATA_F1_1 — Data to program into memory mode register 11. FC=1 Reset Source: ctl_amod_g_rst_n
  [23:16] MR11_DATA_F0_1 — Data to program into memory mode register 11. FC=0 Reset Source: ctl_amod_g_rst_n
  [15:8] MR11_DATA_F2_0 — Data to program into memory mode register 11. FC=2 Reset Source: ctl_amod_g_rst_n
  [7:0] MR11_DATA_F1_0 — Data to program into memory mode register 11. FC=1 Reset Source: ctl_amod_g_rst_n
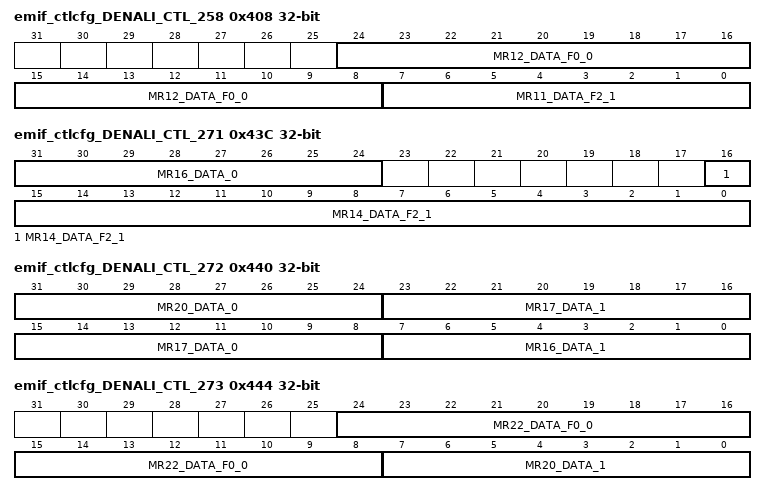
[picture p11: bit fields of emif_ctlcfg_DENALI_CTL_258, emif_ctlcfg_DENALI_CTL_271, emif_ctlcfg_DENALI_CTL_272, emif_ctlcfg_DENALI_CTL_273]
0x408 emif_ctlcfg_DENALI_CTL_258
  [24:8] MR12_DATA_F0_0 — Data to program into memory mode register 12. FC=0 Reset Source: ctl_amod_g_rst_n
  [7:0] MR11_DATA_F2_1 — Data to program into memory mode register 11. FC=2 Reset Source: ctl_amod_g_rst_n
0x40C emif_ctlcfg_DENALI_CTL_259
  [16:0] MR12_DATA_F1_0 — Data to program into memory mode register 12. FC=1 Reset Source: ctl_amod_g_rst_n
0x410 emif_ctlcfg_DENALI_CTL_260
  [16:0] MR12_DATA_F2_0 — Data to program into memory mode register 12. FC=2 Reset Source: ctl_amod_g_rst_n
{0x0+4i} emif_ctlcfg_DENALI_CTL_{i} (i=261..263)
  [16:0] MR12_DATA_F{i-261}_1 — Data to program into memory mode register 12. FC={i-261} Reset Source: ctl_amod_g_rst_n
0x420 emif_ctlcfg_DENALI_CTL_264
  [16:0] MR13_DATA_0 — Data to program into memory mode register 13. Reset Source: ctl_amod_g_rst_n
0x424 emif_ctlcfg_DENALI_CTL_265
  [16:0] MR13_DATA_1 — Data to program into memory mode register 13. Reset Source: ctl_amod_g_rst_n
{0x0+4i} emif_ctlcfg_DENALI_CTL_{i} (i=266..268)
  [16:0] MR14_DATA_F{i-266}_0 — Data to program into memory mode register 14. FC={i-266} Reset Source: ctl_amod_g_rst_n
0x434 emif_ctlcfg_DENALI_CTL_269
  [16:0] MR14_DATA_F0_1 — Data to program into memory mode register 14. FC=0 Reset Source: ctl_amod_g_rst_n
0x438 emif_ctlcfg_DENALI_CTL_270
  [16:0] MR14_DATA_F1_1 — Data to program into memory mode register 14. FC=1 Reset Source: ctl_amod_g_rst_n
0x43C emif_ctlcfg_DENALI_CTL_271
  [31:24] MR16_DATA_0 — Data to program into memory mode register 16. Reset Source: ctl_amod_g_rst_n
  [16:0] MR14_DATA_F2_1 — Data to program into memory mode register 14. FC=2 Reset Source: ctl_amod_g_rst_n
0x440 emif_ctlcfg_DENALI_CTL_272
  [31:24] MR20_DATA_0 — Data to program into memory mode register 20. Reset Source: ctl_amod_g_rst_n
  [23:16] MR17_DATA_1 — Data to program into memory mode register 17. Reset Source: ctl_amod_g_rst_n
  [15:8] MR17_DATA_0 — Data to program into memory mode register 17. Reset Source: ctl_amod_g_rst_n
  [7:0] MR16_DATA_1 — Data to program into memory mode register 16. Reset Source: ctl_amod_g_rst_n
0x444 emif_ctlcfg_DENALI_CTL_273
  [24:8] MR22_DATA_F0_0 — Data to program into memory mode register 22. FC=0 Reset Source: ctl_amod_g_rst_n
  [7:0] MR20_DATA_1 — Data to program into memory mode register 20. Reset Source: ctl_amod_g_rst_n
0x448 emif_ctlcfg_DENALI_CTL_274
  [16:0] MR22_DATA_F1_0 — Data to program into memory mode register 22. FC=1 Reset Source: ctl_amod_g_rst_n
0x44C emif_ctlcfg_DENALI_CTL_275
  [16:0] MR22_DATA_F2_0 — Data to program into memory mode register 22. FC=2 Reset Source: ctl_amod_g_rst_n
{0x0+4i} emif_ctlcfg_DENALI_CTL_{i} (i=276..278)
  [16:0] MR22_DATA_F{i-276}_1 — Data to program into memory mode register 22. FC={i-276} Reset Source: ctl_amod_g_rst_n
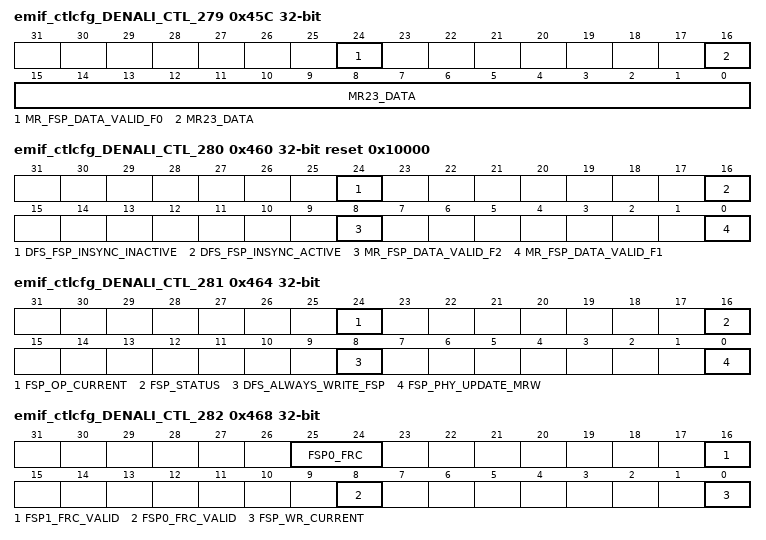
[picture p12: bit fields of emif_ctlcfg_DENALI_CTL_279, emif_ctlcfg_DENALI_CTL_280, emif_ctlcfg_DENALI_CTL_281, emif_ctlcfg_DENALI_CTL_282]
0x45C emif_ctlcfg_DENALI_CTL_279
  [24] MR_FSP_DATA_VALID_F0 — Indicates that, at this frequency, memory was trained and the associated data has been loaded into the MRx_DATA parameter[s]. Value of 1 means memory was trained. FC=0 Reset Source: ctl_amod_g_rst_n
  [16:0] MR23_DATA — Data to program into memory mode register 23. Reset Source: ctl_amod_g_rst_n
0x460 emif_ctlcfg_DENALI_CTL_280 access per field reset 0x10000
  [24] DFS_FSP_INSYNC_INACTIVE ro — When cleared, this indicates that the contents in memcd_param is new that the values in memory's MRx FSP reg and if a dfs occurs, they need to be updated. READ-ONLY Reset Source: ctl_amod_g_rst_n
  [16] DFS_FSP_INSYNC_ACTIVE ro — When cleared, this indicates that the contents in memcd_param is new that the values in memory's MRx FSP reg and if a dfs occurs, they need to be updated. READ-ONLY Reset Source: ctl_amod_g_rst_n
  [8] MR_FSP_DATA_VALID_F2 rw — Indicates that, at this frequency, memory was trained and the associated data has been loaded into the MRx_DATA parameter[s]. Value of 1 means memory was trained. FC=2 Reset Source: ctl_amod_g_rst_n
  [0] MR_FSP_DATA_VALID_F1 rw — Indicates that, at this frequency, memory was trained and the associated data has been loaded into the MRx_DATA parameter[s]. Value of 1 means memory was trained. FC=1 Reset Source: ctl_amod_g_rst_n
0x464 emif_ctlcfg_DENALI_CTL_281
  [24] FSP_OP_CURRENT — Reports which FSP set the memory is currently using. Reset Source: ctl_amod_g_rst_n
  [16] FSP_STATUS — Indicates that a DFS event caused the FSP mode registers to be updated. Value of 1 means that the FSP mode registers were changed. Reset Source: ctl_amod_g_rst_n
  [8] DFS_ALWAYS_WRITE_FSP — Forces all FSP mode registers to be written by the controller during a DFS event. Set to 1 to force the write. Reset Source: ctl_amod_g_rst_n
  [0] FSP_PHY_UPDATE_MRW — Identifies the logic responsible for updating MR12 and MR14 in memory. Clear to 0 for the controller, or set to 1 for the PHY or PI. Reset Source: ctl_amod_g_rst_n
0x468 emif_ctlcfg_DENALI_CTL_282
  [25:24] FSP0_FRC — Identifies which of the controller's frequency copy is associated with FSP0. Reset Source: ctl_amod_g_rst_n
  [16] FSP1_FRC_VALID — Specifies whether the FSP set defined in the FSP1_FRC parameter reflects the frequency used to program the FSP1 registers. Reset Source: ctl_amod_g_rst_n
  [8] FSP0_FRC_VALID — Specifies whether the FSP set defined in the FSP0_FRC parameter reflects the frequency used to program the FSP0 registers. Reset Source: ctl_amod_g_rst_n
  [0] FSP_WR_CURRENT — Reports which FSP set the memory will target with write commands. Reset Source: ctl_amod_g_rst_n
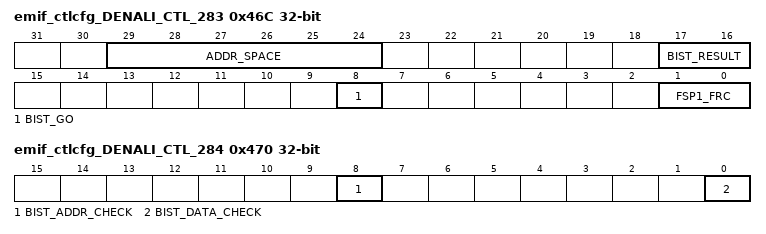
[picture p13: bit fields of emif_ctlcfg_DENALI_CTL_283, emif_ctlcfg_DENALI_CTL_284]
0x46C emif_ctlcfg_DENALI_CTL_283 access per field
  [29:24] ADDR_SPACE rw — Sets the number of address bits to check during BIST operation. Reset Source: ctl_amod_g_rst_n
  [17:16] BIST_RESULT ro — BIST operation status [pass/fail]. Bit [0] indicates data check status and bit [1] indicates address check status. Value of 1 is a passing result. READ-ONLY Reset Source: ctl_amod_g_rst_n
  [8] BIST_GO wo — Initiate a BIST operation. Set to 1 to trigger. WRITE-ONLY Reset Source: ctl_amod_g_rst_n
  [1:0] FSP1_FRC rw — Identifies which of the controller's frequency copy is associated with FSP1. Reset Source: ctl_amod_g_rst_n
0x470 emif_ctlcfg_DENALI_CTL_284
  [8] BIST_ADDR_CHECK — Enable address checking with BIST operation. Set to 1 to enable. Reset Source: ctl_amod_g_rst_n
  [0] BIST_DATA_CHECK — Enable data checking with BIST operation. Set to 1 to enable. Reset Source: ctl_amod_g_rst_n
0x474 emif_ctlcfg_DENALI_CTL_285
  [31:0] BIST_START_ADDRESS_0 — Start BIST checking at this address. Reset Source: ctl_amod_g_rst_n
0x478 emif_ctlcfg_DENALI_CTL_286
  [2:0] BIST_START_ADDRESS_1 — Start BIST checking at this address. Reset Source: ctl_amod_g_rst_n
0x47C emif_ctlcfg_DENALI_CTL_287
  [31:0] BIST_DATA_MASK_0 — Mask applied to data for BIST error checking. Bit [0] controls memory data path bit [0], bit [1] controls memory data path bit [1], etc. Set each bit to 1 to mask. Reset Source: ctl_amod_g_rst_n
